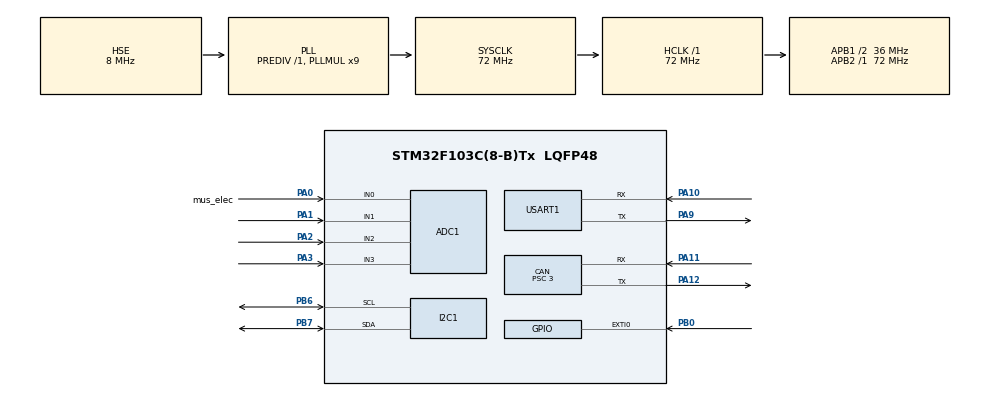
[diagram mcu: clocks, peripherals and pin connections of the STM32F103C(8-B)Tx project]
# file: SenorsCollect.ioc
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ADC1.Channel-1\#ChannelRegularConversion=ADC_CHANNEL_0
ADC1.Channel-2\#ChannelRegularConversion=ADC_CHANNEL_1
ADC1.Channel-3\#ChannelRegularConversion=ADC_CHANNEL_2
ADC1.Channel-4\#ChannelRegularConversion=ADC_CHANNEL_3
ADC1.ContinuousConvMode=DISABLE
ADC1.ExternalTrigConv=ADC_EXTERNALTRIGCONV_T1_CC1
ADC1.NbrOfConversionFlag=1
ADC1.Rank-1\#ChannelRegularConversion=1
ADC1.Rank-2\#ChannelRegularConversion=2
ADC1.Rank-3\#ChannelRegularConversion=3
ADC1.Rank-4\#ChannelRegularConversion=4
ADC1.SamplingTime-1\#ChannelRegularConversion=ADC_SAMPLETIME_1CYCLE_5
ADC1.SamplingTime-2\#ChannelRegularConversion=ADC_SAMPLETIME_1CYCLE_5
ADC1.SamplingTime-3\#ChannelRegularConversion=ADC_SAMPLETIME_1CYCLE_5
ADC1.SamplingTime-4\#ChannelRegularConversion=ADC_SAMPLETIME_1CYCLE_5
ADC1.master=1
CAN.BS1=CAN_BS1_9TQ
CAN.BS2=CAN_BS2_2TQ
CAN.CalculateBaudRate=1000000
CAN.CalculateTimeBit=1000
CAN.CalculateTimeQuantum=83.33333333333333
CAN.NART=ENABLE
CAN.Prescaler=3
Dma.ADC1.2.Direction=DMA_PERIPH_TO_MEMORY
Dma.ADC1.2.Instance=DMA1_Channel1
Dma.ADC1.2.MemDataAlignment=DMA_MDATAALIGN_HALFWORD
Dma.ADC1.2.MemInc=DMA_MINC_ENABLE
Dma.ADC1.2.Mode=DMA_CIRCULAR
Dma.ADC1.2.PeriphDataAlignment=DMA_PDATAALIGN_HALFWORD
Dma.ADC1.2.PeriphInc=DMA_PINC_DISABLE
Dma.ADC1.2.Priority=DMA_PRIORITY_LOW
Dma.Request0=USART1_RX
Dma.Request1=USART1_TX
Dma.Request2=ADC1
Dma.USART1_RX.0.Direction=DMA_PERIPH_TO_MEMORY
Dma.USART1_RX.0.Instance=DMA1_Channel5
Dma.USART1_RX.0.MemDataAlignment=DMA_MDATAALIGN_BYTE
Dma.USART1_RX.0.MemInc=DMA_MINC_ENABLE
Dma.USART1_RX.0.Mode=DMA_CIRCULAR
Dma.USART1_RX.0.PeriphDataAlignment=DMA_PDATAALIGN_BYTE
Dma.USART1_RX.0.PeriphInc=DMA_PINC_DISABLE
Dma.USART1_RX.0.Priority=DMA_PRIORITY_LOW
Dma.USART1_TX.1.Direction=DMA_MEMORY_TO_PERIPH
Dma.USART1_TX.1.Instance=DMA1_Channel4
Dma.USART1_TX.1.MemDataAlignment=DMA_MDATAALIGN_BYTE
Dma.USART1_TX.1.MemInc=DMA_MINC_ENABLE
Dma.USART1_TX.1.Mode=DMA_CIRCULAR
Dma.USART1_TX.1.PeriphDataAlignment=DMA_PDATAALIGN_BYTE
Dma.USART1_TX.1.PeriphInc=DMA_PINC_DISABLE
Dma.USART1_TX.1.Priority=DMA_PRIORITY_LOW
Mcu.Family=STM32F1
Mcu.Name=STM32F103C(8-B)Tx
Mcu.Package=LQFP48
NVIC.DMA1_Channel1_IRQn=true\:0\:0\:false\:false\:true\:false\:true\:true
NVIC.DMA1_Channel4_IRQn=true\:0\:0\:false\:false\:true\:false\:true\:true
NVIC.DMA1_Channel5_IRQn=true\:0\:0\:false\:false\:true\:false\:true\:true
NVIC.EXTI0_IRQn=true\:0\:0\:false\:false\:true\:true\:true\:true
NVIC.PriorityGroup=NVIC_PRIORITYGROUP_4
NVIC.USB_HP_CAN1_TX_IRQn=true\:0\:0\:false\:false\:true\:true\:true\:true
NVIC.USB_LP_CAN1_RX0_IRQn=true\:0\:0\:false\:false\:true\:true\:true\:true
NVIC.CAN1_SCE_IRQn=true\:0\:0\:false\:false\:true\:true\:true\:true
PA0-WKUP.GPIO_Label=mus_elec
PA0-WKUP.Signal=ADCx_IN0
PA1.Signal=ADCx_IN1
PA2.Signal=ADCx_IN2
PA3.Signal=ADCx_IN3
PA10.Mode=Asynchronous
PA10.Signal=USART1_RX
PA11.Mode=CAN_Activate
PA11.Signal=CAN_RX
PA12.Mode=CAN_Activate
PA12.Signal=CAN_TX
PA13.Mode=Serial_Wire
PA13.Signal=SYS_JTMS-SWDIO
PA14.Mode=Serial_Wire
PA14.Signal=SYS_JTCK-SWCLK
PA9.Mode=Asynchronous
PA9.Signal=USART1_TX
PB0.Signal=GPXTI0
PB6.Mode=I2C
PB6.Signal=I2C1_SCL
PB7.Mode=I2C
PB7.Signal=I2C1_SDA
PC14-OSC32_IN.Mode=LSE-External-Oscillator
PC14-OSC32_IN.Signal=RCC_OSC32_IN
PC15-OSC32_OUT.Mode=LSE-External-Oscillator
PC15-OSC32_OUT.Signal=RCC_OSC32_OUT
PD0-OSC_IN.Mode=HSE-External-Oscillator
PD0-OSC_IN.Signal=RCC_OSC_IN
PD1-OSC_OUT.Mode=HSE-External-Oscillator
PD1-OSC_OUT.Signal=RCC_OSC_OUT
ProjectManager.HeapSize=0x200
ProjectManager.StackSize=0x400
ProjectManager.TargetToolchain=CMake
RCC.ADCPresc=RCC_ADCPCLK2_DIV6
RCC.AHBFreq_Value=72000000
RCC.APB1CLKDivider=RCC_HCLK_DIV2
RCC.APB1Freq_Value=36000000
RCC.APB1TimFreq_Value=72000000
RCC.APB2Freq_Value=72000000
RCC.APB2TimFreq_Value=72000000
RCC.HCLKFreq_Value=72000000
RCC.PLLMUL=RCC_PLL_MUL9
RCC.PLLSourceVirtual=RCC_PLLSOURCE_HSE
RCC.SYSCLKFreq_VALUE=72000000
RCC.SYSCLKSource=RCC_SYSCLKSOURCE_PLLCLK
RCC.USBFreq_Value=72000000
SH.ADCx_IN0.0=ADC1_IN0,IN0
SH.ADCx_IN1.0=ADC1_IN1,IN1
SH.ADCx_IN2.0=ADC1_IN2,IN2
SH.ADCx_IN3.0=ADC1_IN3,IN3
TIM1.Channel-PWM\ Generation1\ No\ Output=TIM_CHANNEL_1
TIM1.CounterMode=TIM_COUNTERMODE_UP
TIM1.Period=999
TIM1.Prescaler=71
TIM1.Pulse-PWM\ Generation1\ No\ Output=500
TIM1.RepetitionCounter=0 
TIM1.TIM_MasterOutputTrigger=TIM_TRGO_OC1REF
TIM1.TIM_MasterSlaveMode=TIM_MASTERSLAVEMODE_DISABLE
USART1.VirtualMode=VM_ASYNC
VP_RTC_VS_RTC_Activate.Mode=RTC_Enabled
VP_TIM1_VS_no_output1.Mode=PWM Generation1 No Output
board=custom

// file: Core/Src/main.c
/* USER CODE BEGIN Header */
/**
  ******************************************************************************
  * @file           : main.c
  * @brief          : Main program body
  ******************************************************************************
  * @attention
  *
  * Copyright (c) 2026 STMicroelectronics.
  * All rights reserved.
  *
  * This software is licensed under terms that can be found in the LICENSE file
  * in the root directory of this software component.
  * If no LICENSE file comes with this software, it is provided AS-IS.
  *
  ******************************************************************************
  */
/* USER CODE END Header */
#include "main.h"
#include "adc.h"
#include "can.h"
#include "dma.h"
#include "i2c.h"
#include "rtc.h"
#include "tim.h"
#include "usart.h"
#include "gpio.h"

/* USER CODE BEGIN Includes */
#include "app_service.h"

/* USER CODE END Includes */

void SystemClock_Config(void);

int main(void)
{

  /* MCU Configuration--------------------------------------------------------*/

  /* Reset of all peripherals, Initializes the Flash interface and the Systick. */
  HAL_Init();

  /* Configure the system clock */
  SystemClock_Config();

  /* Initialize all configured peripherals */
  MX_GPIO_Init();
  MX_DMA_Init();
  MX_RTC_Init();
  MX_ADC1_Init();
  MX_CAN_Init();
  MX_TIM1_Init();
  MX_USART1_UART_Init();
  MX_I2C1_Init();
  /* USER CODE BEGIN 2 */
  {
    static const uint8_t boot_msg[] = "BOOT USART1 OK\r\n";
    (void)HAL_UART_Transmit(&huart1, (uint8_t *)boot_msg, (uint16_t)(sizeof(boot_msg) - 1U), 100U);
  }
  /* 应用服务负责事件调度与业务流水线初始化。 */
  if (app_service_init() != 0)
  {
    static const uint8_t fail_msg[] = "APP INIT FAIL\r\n";
    (void)HAL_UART_Transmit(&huart1, (uint8_t *)fail_msg, (uint16_t)(sizeof(fail_msg) - 1U), 100U);
    Error_Handler();
  }

  /* USER CODE END 2 */

  /* Infinite loop */
  while (1)
  {

    /* USER CODE BEGIN 3 */
    app_service_run_once();
  }
  /* USER CODE END 3 */
}

void SystemClock_Config(void)
{
  RCC_OscInitTypeDef RCC_OscInitStruct = {0};
  RCC_ClkInitTypeDef RCC_ClkInitStruct = {0};
  RCC_PeriphCLKInitTypeDef PeriphClkInit = {0};

  /** Initializes the RCC Oscillators according to the specified parameters
  * in the RCC_OscInitTypeDef structure.
  */
  RCC_OscInitStruct.OscillatorType = RCC_OSCILLATORTYPE_LSI|RCC_OSCILLATORTYPE_HSE;
  RCC_OscInitStruct.HSEState = RCC_HSE_ON;
  RCC_OscInitStruct.HSEPredivValue = RCC_HSE_PREDIV_DIV1;
  RCC_OscInitStruct.LSIState = RCC_LSI_ON;
  RCC_OscInitStruct.PLL.PLLState = RCC_PLL_ON;
  RCC_OscInitStruct.PLL.PLLSource = RCC_PLLSOURCE_HSE;
  RCC_OscInitStruct.PLL.PLLMUL = RCC_PLL_MUL9;
  if (HAL_RCC_OscConfig(&RCC_OscInitStruct) != HAL_OK)
  {
    Error_Handler();
  }

  /** Initializes the CPU, AHB and APB buses clocks
  */
  RCC_ClkInitStruct.ClockType = RCC_CLOCKTYPE_HCLK|RCC_CLOCKTYPE_SYSCLK
                              |RCC_CLOCKTYPE_PCLK1|RCC_CLOCKTYPE_PCLK2;
  RCC_ClkInitStruct.SYSCLKSource = RCC_SYSCLKSOURCE_PLLCLK;
  RCC_ClkInitStruct.AHBCLKDivider = RCC_SYSCLK_DIV1;
  RCC_ClkInitStruct.APB1CLKDivider = RCC_HCLK_DIV2;
  RCC_ClkInitStruct.APB2CLKDivider = RCC_HCLK_DIV1;

  if (HAL_RCC_ClockConfig(&RCC_ClkInitStruct, FLASH_LATENCY_2) != HAL_OK)
  {
    Error_Handler();
  }
  PeriphClkInit.PeriphClockSelection = RCC_PERIPHCLK_RTC|RCC_PERIPHCLK_ADC;
  PeriphClkInit.RTCClockSelection = RCC_RTCCLKSOURCE_LSI;
  PeriphClkInit.AdcClockSelection = RCC_ADCPCLK2_DIV6;
  if (HAL_RCCEx_PeriphCLKConfig(&PeriphClkInit) != HAL_OK)
  {
    Error_Handler();
  }
}

void Error_Handler(void)
{
  __disable_irq();
  while (1)
  {
  }
}
